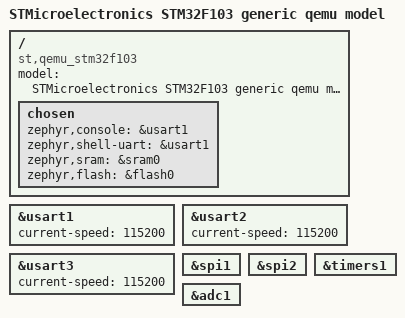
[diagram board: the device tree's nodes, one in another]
/*
 * Copyright (c) 2017 Linaro Limited
 *
 * SPDX-License-Identifier: Apache-2.0
 */

/dts-v1/;
#include <st/f1/stm32f103Xb.dtsi>

/ {
	model = "STMicroelectronics STM32F103 generic qemu model";
	compatible = "st,qemu_stm32f103", "st,stm32f103rb";

	chosen {
		zephyr,console = &usart1;
		zephyr,shell-uart = &usart1;
		zephyr,sram = &sram0;
		zephyr,flash = &flash0;
	};
};

&usart1 {
	current-speed = <115200>;
	status = "okay";
};

&usart2 {
	current-speed = <115200>;
};

&usart3 {
	current-speed = <115200>;
};

&spi1 {
	status = "okay";
};

&spi2 {
	status = "okay";
};

&timers1 {
	status = "okay";
};

&adc1 {
	status = "okay";
};
